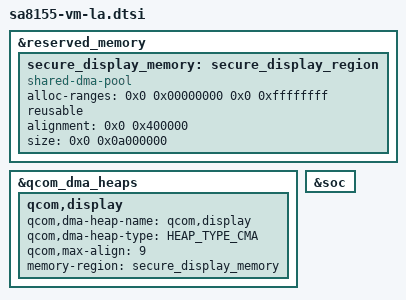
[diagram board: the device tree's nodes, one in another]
&reserved_memory {
	secure_display_memory: secure_display_region {
		compatible = "shared-dma-pool";
		alloc-ranges = <0x0 0x00000000 0x0 0xffffffff>;
		reusable;
		alignment = <0x0 0x400000>;
		size = <0x0 0x0a000000>;
	};
};

&qcom_dma_heaps {
	qcom,display {
		qcom,dma-heap-name = "qcom,display";
		qcom,dma-heap-type = <HEAP_TYPE_CMA>;
		qcom,max-align = <9>;
		memory-region = <&secure_display_memory>;
	};
};

&soc {
};
